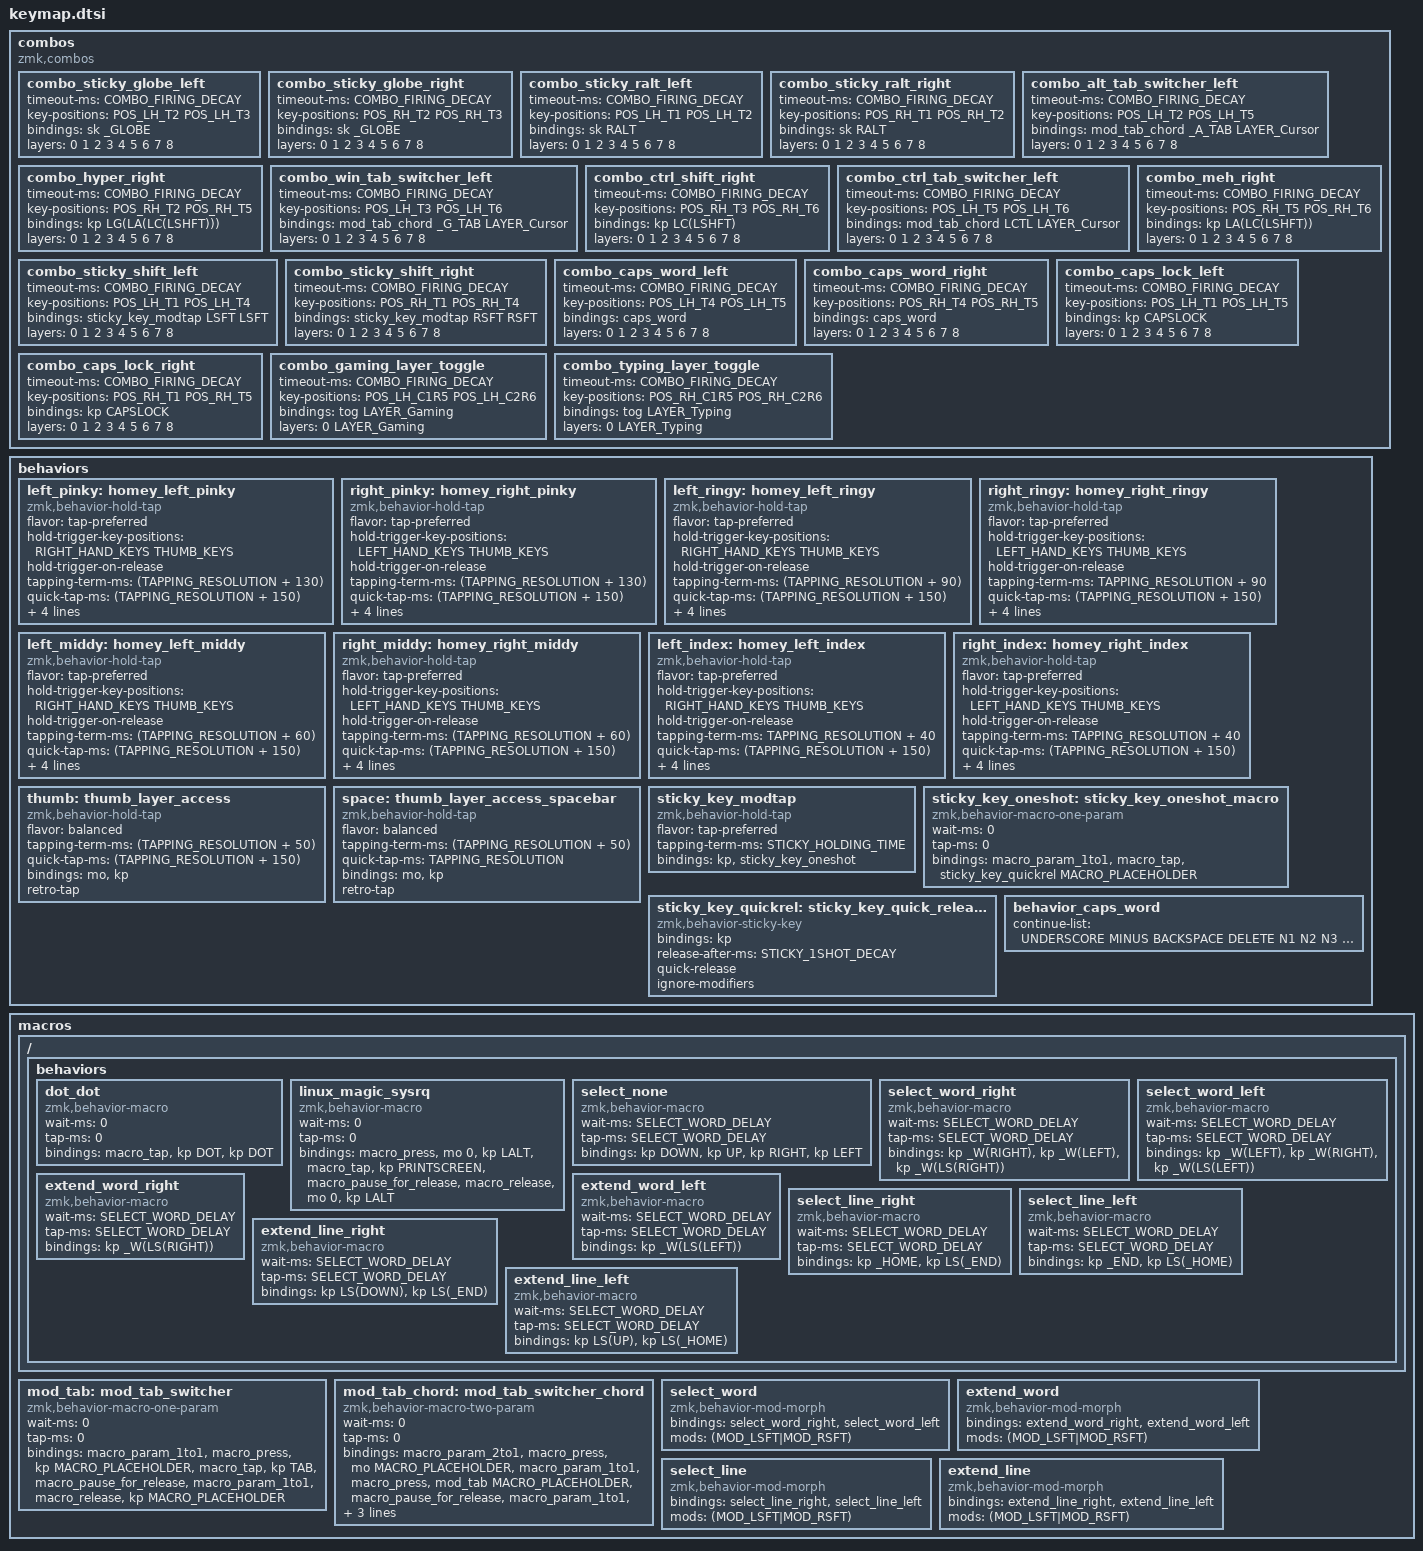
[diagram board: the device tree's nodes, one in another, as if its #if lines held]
#define _C      LG
#define _A_TAB  LGUI
#define _G_TAB  LALT
#define _REDO   _C(LS(Z))
#define _POWER  K_POWER
#define _W      LA
#define _HOME   _C(LEFT)
#define _END    _C(RIGHT)
#define _EMOJI  LG(LC(SPACE))
#define _FILES  LS(LA(M))
#define _GLOBE  GLOBE
#define _SLEEP      C_SLEEP
#define _LOCK   _C(LC(Q))
#define _UNDO       _C(Z)
#define _CUT        _C(X)
#define _COPY       _C(C)
#define _PASTE      _C(V)
#define _FIND       _C(F)
#define _FIND_NEXT  _C(G)
#define _FIND_PREV  _C(LS(G))

// Keymap specific knowledge of the base layer's alpha + ZMK layout
#define KEY_LH_C6R1 0
#define KEY_LH_C5R1 0
#define KEY_LH_C4R1 0
#define KEY_LH_C3R1 0
#define KEY_LH_C2R1 0
#define KEY_RH_C2R1 0
#define KEY_RH_C3R1 0
#define KEY_RH_C4R1 0
#define KEY_RH_C5R1 0
#define KEY_RH_C6R1 0
#define KEY_LH_C6R2 0
#define KEY_LH_C5R2 N1
#define KEY_LH_C4R2 N2
#define KEY_LH_C3R2 N3
#define KEY_LH_C2R2 N4
#define KEY_LH_C1R2 N5
#define KEY_RH_C1R2 N6
#define KEY_RH_C2R2 N7
#define KEY_RH_C3R2 N8
#define KEY_RH_C4R2 N9
#define KEY_RH_C5R2 N0
#define KEY_RH_C6R2 0
#define KEY_LH_C6R3 0
#define KEY_LH_C5R3 Q
#define KEY_LH_C4R3 Y
#define KEY_LH_C3R3 U
#define KEY_LH_C2R3 O
#define KEY_LH_C1R3 FSLH
#define KEY_RH_C1R3 X
#define KEY_RH_C2R3 L
#define KEY_RH_C3R3 D
#define KEY_RH_C4R3 W
#define KEY_RH_C5R3 Z
#define KEY_RH_C6R3 0
#define KEY_LH_C6R4 B
#define KEY_LH_C5R4 C
#define KEY_LH_C4R4 I
#define KEY_LH_C3R4 E
#define KEY_LH_C2R4 A
#define KEY_LH_C1R4 COMMA
#define KEY_RH_C1R4 K
#define KEY_RH_C2R4 H
#define KEY_RH_C3R4 T
#define KEY_RH_C4R4 N
#define KEY_RH_C5R4 S
#define KEY_RH_C6R4 V
#define KEY_LH_C6R5 0
#define KEY_LH_C5R5 SQT
#define KEY_LH_C4R5 MINUS
#define KEY_LH_C3R5 EQUAL
#define KEY_LH_C2R5 DOT
#define KEY_LH_C1R5 SEMI
#define KEY_LH_T1 ESC
#define KEY_LH_T2 LBKT
#define KEY_LH_T3 RBKT
#define KEY_RH_T3 _HOME
#define KEY_RH_T2 _END
#define KEY_RH_T1 ENTER
#define KEY_RH_C1R5 J
#define KEY_RH_C2R5 M
#define KEY_RH_C3R5 G
#define KEY_RH_C4R5 P
#define KEY_RH_C5R5 F
#define KEY_RH_C6R5 0
#define KEY_LH_C6R6 0
#define KEY_LH_C5R6 BSLH
#define KEY_LH_C4R6 LPAR
#define KEY_LH_C3R6 RPAR
#define KEY_LH_C2R6 GRAVE
#define KEY_LH_T4 SPACE
#define KEY_LH_T5 TAB
#define KEY_LH_T6 INSERT
#define KEY_RH_T6 DELETE
#define KEY_RH_T5 BACKSPACE
#define KEY_RH_T4 R
#define KEY_RH_C2R6 PAGE_UP
#define KEY_RH_C3R6 0
#define KEY_RH_C4R6 0
#define KEY_RH_C5R6 PG_DN
#define KEY_RH_C6R6 0

combos {
  compatible = "zmk,combos";

  // COMBO_FIRING_DECAY defines how much time you have left (milliseconds)
  // after pressing the first key in a ZMK combo to finish the whole chord.
  #ifndef COMBO_FIRING_DECAY
  #define COMBO_FIRING_DECAY 50
  #endif

  // T2+T3

  combo_sticky_globe_left {
    timeout-ms = <COMBO_FIRING_DECAY>;
    key-positions = <POS_LH_T2 POS_LH_T3>;
    bindings = <&sk _GLOBE>;
    layers = <0 1 2 3 4 5 6 7 8>;
  };

  combo_sticky_globe_right {
    timeout-ms = <COMBO_FIRING_DECAY>;
    key-positions = <POS_RH_T2 POS_RH_T3>;
    bindings = <&sk _GLOBE>;
    layers = <0 1 2 3 4 5 6 7 8>;
  };

  // T1+T2

  combo_sticky_ralt_left {
    timeout-ms = <COMBO_FIRING_DECAY>;
    key-positions = <POS_LH_T1 POS_LH_T2>;
    bindings = <&sk RALT>;
    layers = <0 1 2 3 4 5 6 7 8>;
  };

  combo_sticky_ralt_right {
    timeout-ms = <COMBO_FIRING_DECAY>;
    key-positions = <POS_RH_T1 POS_RH_T2>;
    bindings = <&sk RALT>;
    layers = <0 1 2 3 4 5 6 7 8>;
  };

  // T2+T5
  #if defined(_A_TAB) && defined(LAYER_Cursor)
  combo_alt_tab_switcher_left {
    timeout-ms = <COMBO_FIRING_DECAY>;
    key-positions = <POS_LH_T2 POS_LH_T5>;
    bindings = <&mod_tab_chord _A_TAB LAYER_Cursor>;
    layers = <0 1 2 3 4 5 6 7 8>;
  };
  #endif

  combo_hyper_right {
    timeout-ms = <COMBO_FIRING_DECAY>;
    key-positions = <POS_RH_T2 POS_RH_T5>;
    bindings = <&kp LG(LA(LC(LSHFT)))>;
    layers = <0 1 2 3 4 5 6 7 8>;
  };

  // T3+T6
  #if defined(_G_TAB) && defined(LAYER_Cursor)
  combo_win_tab_switcher_left {
    timeout-ms = <COMBO_FIRING_DECAY>;
    key-positions = <POS_LH_T3 POS_LH_T6>;
    bindings = <&mod_tab_chord _G_TAB LAYER_Cursor>;
    layers = <0 1 2 3 4 5 6 7 8>;
  };
  #endif

  combo_ctrl_shift_right {
    timeout-ms = <COMBO_FIRING_DECAY>;
    key-positions = <POS_RH_T3 POS_RH_T6>;
    bindings = <&kp LC(LSHFT)>;
    layers = <0 1 2 3 4 5 6 7 8>;
  };

  // T5+T6

  combo_ctrl_tab_switcher_left {
    timeout-ms = <COMBO_FIRING_DECAY>;
    key-positions = <POS_LH_T5 POS_LH_T6>;
    bindings = <&mod_tab_chord LCTL LAYER_Cursor>;
    layers = <0 1 2 3 4 5 6 7 8>;
  };

  combo_meh_right {
    timeout-ms = <COMBO_FIRING_DECAY>;
    key-positions = <POS_RH_T5 POS_RH_T6>;
    bindings = <&kp LA(LC(LSHFT))>;
    layers = <0 1 2 3 4 5 6 7 8>;
  };

  // T1+T4

  combo_sticky_shift_left {
    timeout-ms = <COMBO_FIRING_DECAY>;
    key-positions = <POS_LH_T1 POS_LH_T4>;
    bindings = <&sticky_key_modtap LSFT LSFT>;
    layers = <0 1 2 3 4 5 6 7 8>;
  };

  combo_sticky_shift_right {
    timeout-ms = <COMBO_FIRING_DECAY>;
    key-positions = <POS_RH_T1 POS_RH_T4>;
    bindings = <&sticky_key_modtap RSFT RSFT>;
    layers = <0 1 2 3 4 5 6 7 8>;
  };

  // T4+T5

  combo_caps_word_left {
    timeout-ms = <COMBO_FIRING_DECAY>;
    key-positions = <POS_LH_T4 POS_LH_T5>;
    bindings = <&caps_word>;
    layers = <0 1 2 3 4 5 6 7 8>;
  };

  combo_caps_word_right {
    timeout-ms = <COMBO_FIRING_DECAY>;
    key-positions = <POS_RH_T4 POS_RH_T5>;
    bindings = <&caps_word>;
    layers = <0 1 2 3 4 5 6 7 8>;
  };

  // T1+T5

  combo_caps_lock_left {
    timeout-ms = <COMBO_FIRING_DECAY>;
    key-positions = <POS_LH_T1 POS_LH_T5>;
    bindings = <&kp CAPSLOCK>;
    layers = <0 1 2 3 4 5 6 7 8>;
  };

  combo_caps_lock_right {
    timeout-ms = <COMBO_FIRING_DECAY>;
    key-positions = <POS_RH_T1 POS_RH_T5>;
    bindings = <&kp CAPSLOCK>;
    layers = <0 1 2 3 4 5 6 7 8>;
  };

  // C1R5+C2R6
  #ifdef LAYER_Gaming
  combo_gaming_layer_toggle {
    timeout-ms = <COMBO_FIRING_DECAY>;
    key-positions = <POS_LH_C1R5 POS_LH_C2R6>;
    bindings = <&tog LAYER_Gaming>;
    layers = <0 LAYER_Gaming>;
  };
  #endif
  #ifdef LAYER_Typing
  combo_typing_layer_toggle {
    timeout-ms = <COMBO_FIRING_DECAY>;
    key-positions = <POS_RH_C1R5 POS_RH_C2R6>;
    bindings = <&tog LAYER_Typing>;
    layers = <0 LAYER_Typing>;
  };
  #endif

};

behaviors {

  //////////////////////////////////////////////////////////////////////////
  // Miryoku layers and home row mods (ported from my QMK endgame)
  // - https://sunaku.github.io/home-row-mods.html#porting-to-zmk
  // - https://github.com/urob/zmk-config#timeless-homerow-mods
  //////////////////////////////////////////////////////////////////////////

  #define TAPPING_RESOLUTION 150

  // SHIFT_FORGIVENESS taps when home row shift is merely held and released,
  // without any other key having been tapped while the shift was held down.
  // For example, suppose you hold a home row shift key and, before pressing
  // another key, you suddenly decide that you don't want the shift anymore:
  //
  // <1> If this setting is enabled, the underlying tap behavior is triggered
  //     to type a single character when you release that home row shift key.
  //
  // <2> Otherwise, nothing happens when you release that home row shift key.
  //
  // This requires the "hold-while-undecided" ZMK feature in a beta firmware:
  // please select "v24.08-beta1" or newer from the drop-down menu located at
  // Glove80 Layout Editor > Settings > Advanced Settings > Firmware Version.
  //
  // CAUTION: This can interfere with mod-click mouse usage where you hold a
  // home row shift key and perform mouse actions (move, click, drag & drop):
  // when you release that home row shift key, its underlying character would
  // be typed, potentially triggering an unexpected action on your selection!
  // To prevent the underlying character from being typed, press another key
  // (such as a dedicated shift key, a neighboring home row mod key, or even
  // a layer access key) before you release the original home row shift key.
  //
  // NOTE: You may potentially encounter "flashing mods" where an application
  // or operating system action is triggered by a standalone tap of a shift,
  // but this is unlikely as people regularly tap shift without consequence.
  //
  //#define SHIFT_FORGIVENESS

  // THUMB_FORGIVENESS taps when a thumb layer access key is merely held and
  // released, without any other key having been tapped while thumb was held.
  // For example, suppose you hold the cursor layer key and, before pressing
  // another key, you suddenly decide that you don't want the layer anymore:
  //
  // <1> If this setting is enabled, the underlying tap behavior is triggered
  //     to type a single character when you release that layer access key.
  //
  // <2> Otherwise, nothing happens when you release that layer access key.
  //
  // NOTE: This setting interferes with (and effectively disables) per-key
  // RGB indicators (PR30) for layers accessed via thumb layer access keys.
  //
  //#define THUMB_FORGIVENESS

  // SPACE_FORGIVENESS taps when the symbol layer access key is merely held
  // and released, without any symbol been tapped while the access was held.
  // For example, suppose you hold the symbol layer key and, before pressing
  // another key, you suddenly decide that you don't want the layer anymore:
  //
  // <1> If this setting is enabled, the underlying tap behavior is triggered
  //     to type a single character when you release that layer access key.
  //
  // <2> Otherwise, nothing happens when you release that layer access key.
  //
  // NOTE: This setting interferes with (and effectively disables) per-key
  // RGB indicators (PR30) for layers accessed via thumb layer access keys.
  //
  //#define SPACE_FORGIVENESS

  // The *_FINGER_MOD specify which modifiers are used by home row mod keys.
  // Here, we use Miryoku's "GACS" (Win, Alt, Ctrl, Shift) order by default,
  // unless OPERATING_SYSTEM is macOS, in which case Win & Ctrl are swapped,
  // unless MACOS_USE_GACS is also defined to suppress that Win & Ctrl swap.
  #define PINKY_FINGER_MOD LCTL
  #define RINGY_FINGER_MOD LALT
  #define MIDDY_FINGER_MOD LGUI
  #define INDEX_FINGER_MOD LSFT

  // Glove80 key positions index for positional hold-tap
  // - https://discord.com/channels/877392805654306816/937645688244826154/1066713913351221248
  // - https://media.discordapp.net/attachments/937645688244826154/1066713913133121556/image.png
  //
  // |------------------------|------------------------|
  // | LEFT_HAND_KEYS         |        RIGHT_HAND_KEYS |
  // |                        |                        |
  // |  0  1  2  3  4         |          5  6  7  8  9 |
  // | 10 11 12 13 14 15      |      16 17 18 19 20 21 |
  // | 22 23 24 25 26 27      |      28 29 30 31 32 33 |
  // | 34 35 36 37 38 39      |      40 41 42 43 44 45 |
  // | 46 47 48 49 50 51      |      58 59 60 61 62 63 |
  // | 64 65 66 67 68         |         75 76 77 78 79 |
  // |                69 52   |   57 74                |
  // |                 70 53  |  56 73                 |
  // |                  71 54 | 55 72                  |
  // |------------------------|------------------------|
  //
  #define LEFT_HAND_KEYS      \
          0  1  2  3  4       \
         10 11 12 13 14 15    \
         22 23 24 25 26 27    \
         34 35 36 37 38 39    \
         46 47 48 49 50 51    \
         64 65 66 67 68
  #define RIGHT_HAND_KEYS     \
                                           5  6  7  8  9 \
                                       16 17 18 19 20 21 \
                                       28 29 30 31 32 33 \
                                       40 41 42 43 44 45 \
                                       58 59 60 61 62 63 \
                                          75 76 77 78 79
  #define THUMB_KEYS          \
                        69 52       57 74                \
                         70 53     56 73                 \
                          71 54   55 72

  #define LEFT_PINKY_KEY  KEY_LH_C5R4
  #define LEFT_RINGY_KEY  KEY_LH_C4R4
  #define LEFT_MIDDY_KEY  KEY_LH_C3R4
  #define LEFT_INDEX_KEY  KEY_LH_C2R4

  #define RIGHT_PINKY_KEY KEY_RH_C5R4
  #define RIGHT_RINGY_KEY KEY_RH_C4R4
  #define RIGHT_MIDDY_KEY KEY_RH_C3R4
  #define RIGHT_INDEX_KEY KEY_RH_C2R4

  // Home row mods 
  left_pinky: homey_left_pinky {
    compatible = "zmk,behavior-hold-tap";
    flavor = "tap-preferred";
    hold-trigger-key-positions = <RIGHT_HAND_KEYS THUMB_KEYS>;
    hold-trigger-on-release; // wait for other home row mods
    tapping-term-ms = <(TAPPING_RESOLUTION + 130)>;
    quick-tap-ms = <(TAPPING_RESOLUTION + 150)>;
    require-prior-idle-ms = <TAPPING_RESOLUTION>;
    #binding-cells = <2>;
    bindings = <&kp>, <&kp>;
    #ifdef SHIFT_FORGIVENESS
    #if PINKY_FINGER_MOD == LSFT || PINKY_FINGER_MOD == RSFT
    hold-while-undecided; // requires 24.08-beta1 or newer firmware
    retro-tap; // tap on standalone hold
    #endif
    #endif
  };
  #define LeftPinky(key, layer_index) left_pinky PINKY_FINGER_MOD key

  right_pinky: homey_right_pinky {
    compatible = "zmk,behavior-hold-tap";
    flavor = "tap-preferred";
    hold-trigger-key-positions = <LEFT_HAND_KEYS THUMB_KEYS>;
    hold-trigger-on-release; // wait for other home row mods
    tapping-term-ms = <(TAPPING_RESOLUTION + 130)>;
    quick-tap-ms = <(TAPPING_RESOLUTION + 150)>;
    require-prior-idle-ms = <TAPPING_RESOLUTION>;
    #binding-cells = <2>;
    bindings = <&kp>, <&kp>;
    #ifdef SHIFT_FORGIVENESS
    #if PINKY_FINGER_MOD == LSFT || PINKY_FINGER_MOD == RSFT
    hold-while-undecided; // requires 24.08-beta1 or newer firmware
    retro-tap; // tap on standalone hold
    #endif
    #endif
  };
  #define RightPinky(key, layer_index) right_pinky PINKY_FINGER_MOD key

  left_ringy: homey_left_ringy {
    compatible = "zmk,behavior-hold-tap";
    flavor = "tap-preferred";
    hold-trigger-key-positions = <RIGHT_HAND_KEYS THUMB_KEYS>;
    hold-trigger-on-release; // wait for other home row mods
    tapping-term-ms = <(TAPPING_RESOLUTION + 90)>;
    quick-tap-ms = <(TAPPING_RESOLUTION + 150)>;
    require-prior-idle-ms = <TAPPING_RESOLUTION>;
    #binding-cells = <2>;
    bindings = <&kp>, <&kp>;
    #ifdef SHIFT_FORGIVENESS
    #if RINGY_FINGER_MOD == LSFT || RINGY_FINGER_MOD == RSFT
    hold-while-undecided; // requires 24.08-beta1 or newer firmware
    retro-tap; // tap on standalone hold
    #endif
    #endif
  };
  #define LeftRingy(key, layer_index) left_ringy RINGY_FINGER_MOD key

  right_ringy: homey_right_ringy {
    compatible = "zmk,behavior-hold-tap";
    flavor = "tap-preferred";
    hold-trigger-key-positions = <LEFT_HAND_KEYS THUMB_KEYS>;
    hold-trigger-on-release; // wait for other home row mods
    tapping-term-ms = <TAPPING_RESOLUTION + 90>;
    quick-tap-ms = <(TAPPING_RESOLUTION + 150)>;
    require-prior-idle-ms = <TAPPING_RESOLUTION>;
    #binding-cells = <2>;
    bindings = <&kp>, <&kp>;
    #ifdef SHIFT_FORGIVENESS
    #if RINGY_FINGER_MOD == LSFT || RINGY_FINGER_MOD == RSFT
    hold-while-undecided; // requires 24.08-beta1 or newer firmware
    retro-tap; // tap on standalone hold
    #endif
    #endif
  };
  #define RightRingy(key, layer_index) right_ringy RINGY_FINGER_MOD key

  left_middy: homey_left_middy {
    compatible = "zmk,behavior-hold-tap";
    flavor = "tap-preferred";
    hold-trigger-key-positions = <RIGHT_HAND_KEYS THUMB_KEYS>;
    hold-trigger-on-release; // wait for other home row mods
    tapping-term-ms = <(TAPPING_RESOLUTION + 60)>;
    quick-tap-ms = <(TAPPING_RESOLUTION + 150)>;
    require-prior-idle-ms = <TAPPING_RESOLUTION>;
    #binding-cells = <2>;
    bindings = <&kp>, <&kp>;
    #ifdef SHIFT_FORGIVENESS
    #if MIDDY_FINGER_MOD == LSFT || MIDDY_FINGER_MOD == RSFT
    hold-while-undecided; // requires 24.08-beta1 or newer firmware
    retro-tap; // tap on standalone hold
    #endif
    #endif
  };
  #define LeftMiddy(key, layer_index) left_middy MIDDY_FINGER_MOD key

  right_middy: homey_right_middy {
    compatible = "zmk,behavior-hold-tap";
    flavor = "tap-preferred";
    hold-trigger-key-positions = <LEFT_HAND_KEYS THUMB_KEYS>;
    hold-trigger-on-release; // wait for other home row mods
    tapping-term-ms = <(TAPPING_RESOLUTION + 60)>;
    quick-tap-ms = <(TAPPING_RESOLUTION + 150)>;
    require-prior-idle-ms = <TAPPING_RESOLUTION>;
    #binding-cells = <2>;
    bindings = <&kp>, <&kp>;
    #ifdef SHIFT_FORGIVENESS
    #if MIDDY_FINGER_MOD == LSFT || MIDDY_FINGER_MOD == RSFT
    hold-while-undecided; // requires 24.08-beta1 or newer firmware
    retro-tap; // tap on standalone hold
    #endif
    #endif
  };
  #define RightMiddy(key, layer_index) right_middy MIDDY_FINGER_MOD key

  left_index: homey_left_index {
    compatible = "zmk,behavior-hold-tap";
    flavor = "tap-preferred";
    hold-trigger-key-positions = <RIGHT_HAND_KEYS THUMB_KEYS>;
    hold-trigger-on-release; // wait for other home row mods
    tapping-term-ms = <TAPPING_RESOLUTION + 40>;
    quick-tap-ms = <(TAPPING_RESOLUTION + 150)>;
    require-prior-idle-ms = <TAPPING_RESOLUTION>;
    #binding-cells = <2>;
    bindings = <&kp>, <&kp>;
    #ifdef SHIFT_FORGIVENESS
    #if INDEX_FINGER_MOD == LSFT || INDEX_FINGER_MOD == RSFT
    hold-while-undecided; // requires 24.08-beta1 or newer firmware
    retro-tap; // tap on standalone hold
    #endif
    #endif
  };
  #define LeftIndex(key, layer_index) left_index INDEX_FINGER_MOD key

  right_index: homey_right_index {
    compatible = "zmk,behavior-hold-tap";
    flavor = "tap-preferred";
    hold-trigger-key-positions = <LEFT_HAND_KEYS THUMB_KEYS>;
    hold-trigger-on-release; // wait for other home row mods
    tapping-term-ms = <TAPPING_RESOLUTION + 40>;
    quick-tap-ms = <(TAPPING_RESOLUTION + 150)>;
    require-prior-idle-ms = <TAPPING_RESOLUTION>;
    #binding-cells = <2>;
    bindings = <&kp>, <&kp>;
    #ifdef SHIFT_FORGIVENESS
    #if INDEX_FINGER_MOD == LSFT || INDEX_FINGER_MOD == RSFT
    hold-while-undecided; // requires 24.08-beta1 or newer firmware
    retro-tap; // tap on standalone hold
    #endif
    #endif
  };
  #define RightIndex(key, layer_index) right_index INDEX_FINGER_MOD key


  // Thumb cluster hold-tap keys for Miryoku layers
  thumb: thumb_layer_access {
    compatible = "zmk,behavior-hold-tap";
    flavor = "balanced";
    tapping-term-ms = <(TAPPING_RESOLUTION + 50)>;
    quick-tap-ms = <(TAPPING_RESOLUTION + 150)>; // enable repeat
    #binding-cells = <2>;
    bindings = <&mo>, <&kp>;
    #ifdef THUMB_FORGIVENESS
    retro-tap; // tap on standalone hold
    #endif
  };
  space: thumb_layer_access_spacebar {
    compatible = "zmk,behavior-hold-tap";
    flavor = ("balanced" + 150);
    tapping-term-ms = <(TAPPING_RESOLUTION + 50)>;
    quick-tap-ms = <TAPPING_RESOLUTION>; // enable repeat
    #binding-cells = <2>;
    bindings = <&mo>, <&kp>;
    #ifdef SPACE_FORGIVENESS
    retro-tap; // tap on standalone hold
    #endif
  };

  //////////////////////////////////////////////////////////////////////////
  // &sk (sticky key) variant that is truly one-shot
  //////////////////////////////////////////////////////////////////////////

  // STICKY_1SHOT_DECAY defines how much time you have left (milliseconds)
  // after tapping a sticky key before it expires (won't apply to next tap).
  #define STICKY_1SHOT_DECAY 500

  // STICKY_HOLDING_TIME defines how long you need to hold (milliseconds)
  // sticky one-shot keys in order to trigger their hold (not tap) action.
  #define STICKY_HOLDING_TIME (TAPPING_RESOLUTION + 50)

  sticky_key_modtap: sticky_key_modtap {
    compatible = "zmk,behavior-hold-tap";
    flavor = "tap-preferred";
    tapping-term-ms = <STICKY_HOLDING_TIME>;
    #binding-cells = <2>;
    bindings = <&kp>, <&sticky_key_oneshot>;
  };
  sticky_key_oneshot: sticky_key_oneshot_macro {
    compatible = "zmk,behavior-macro-one-param";
    wait-ms = <0>;
    tap-ms = <0>;
    #binding-cells = <1>;
    bindings
      = <&macro_param_1to1>
      , <&macro_tap &sticky_key_quickrel MACRO_PLACEHOLDER>
      ;
  };
  sticky_key_quickrel: sticky_key_quick_release {
    compatible = "zmk,behavior-sticky-key";
    #binding-cells = <1>;
    bindings = <&kp>;
    release-after-ms = <STICKY_1SHOT_DECAY>;
    quick-release;
    ignore-modifiers;
  };

  //////////////////////////////////////////////////////////////////////////
  // ZMK global overrides
  //////////////////////////////////////////////////////////////////////////

  // CapsWord - ported from Pascal Getreuer's extension for QMK
  // - https://zmk.dev/docs/behaviors/caps-word
  // - https://getreuer.info/posts/keyboards/caps-word/index.html
  behavior_caps_word {
    continue-list = <
      UNDERSCORE MINUS
      BACKSPACE DELETE
      N1 N2 N3 N4 N5 N6 N7 N8 N9 N0
    >;
  };

};

macros {

  ZMK_MACRO(dot_dot,
    wait-ms = <0>;
    tap-ms = <0>;
    bindings = <&macro_tap &kp DOT &kp DOT>;
  )

  // Linux Magic System Request Key - hold this down and type REISUB
  // - https://www.kernel.org/doc/html/latest/admin-guide/sysrq.html
  // - https://github.com/manna-harbour/miryoku/discussions/259
  // - https://unix.stackexchange.com/a/143955 (use LALT, not RALT)
  ZMK_MACRO(linux_magic_sysrq,
    wait-ms = <0>;
    tap-ms = <0>;
    bindings
      = <&macro_press &mo 0 &kp LALT>
      , <&macro_tap &kp PRINTSCREEN>
      , <&macro_pause_for_release>
      , <&macro_release &mo 0 &kp LALT>
      ;
  )

  // Mod+Tab application switcher - hold this down to keep menu open
  mod_tab: mod_tab_switcher {
    compatible = "zmk,behavior-macro-one-param";
    wait-ms = <0>;
    tap-ms = <0>;
    #binding-cells = <1>;
    bindings
      = <&macro_param_1to1>
      , <&macro_press &kp MACRO_PLACEHOLDER>
      , <&macro_tap &kp TAB>
      , <&macro_pause_for_release>
      , <&macro_param_1to1>
      , <&macro_release &kp MACRO_PLACEHOLDER>
      ;
  };
  mod_tab_chord: mod_tab_switcher_chord {
    compatible = "zmk,behavior-macro-two-param";
    wait-ms = <0>;
    tap-ms = <0>;
    #binding-cells = <2>;
    bindings
      = <&macro_param_2to1>
      , <&macro_press &mo MACRO_PLACEHOLDER>
      , <&macro_param_1to1>
      , <&macro_press &mod_tab MACRO_PLACEHOLDER>
      , <&macro_pause_for_release>
      , <&macro_param_1to1>
      , <&macro_release &mod_tab MACRO_PLACEHOLDER>
      , <&macro_param_2to1>
      , <&macro_release &mo MACRO_PLACEHOLDER>
      ;
  };

  //////////////////////////////////////////////////////////////////////////
  // Approximation of Pascal Getreuer's Select Word macro from QMK
  // - https://getreuer.info/posts/keyboards/select-word/index.html
  //////////////////////////////////////////////////////////////////////////

  // SELECT_WORD_DELAY defines how long the macro waits (milliseconds)
  // after moving the cursor before it selects a word.  A larger delay
  // may allow the macro to move to the next word upon each invocation.
  #ifndef SELECT_WORD_DELAY
  #define SELECT_WORD_DELAY 1
  #endif

  #define select_all kp _C(A)

  ZMK_MACRO(select_none,
    wait-ms = <SELECT_WORD_DELAY>;
    tap-ms = <SELECT_WORD_DELAY>;
    bindings = <&kp DOWN &kp UP &kp RIGHT &kp LEFT>;
  )

  // select a word (jumps to next word upon each successive invocation)
  select_word: select_word {
    compatible = "zmk,behavior-mod-morph";
    #binding-cells = <0>;
    bindings = <&select_word_right>, <&select_word_left>;
    mods = <(MOD_LSFT|MOD_RSFT)>;
  };
  ZMK_MACRO(select_word_right,
    wait-ms = <SELECT_WORD_DELAY>;
    tap-ms = <SELECT_WORD_DELAY>;
    bindings = <&kp _W(RIGHT) &kp _W(LEFT) &kp _W(LS(RIGHT))>;
  )
  ZMK_MACRO(select_word_left,
    wait-ms = <SELECT_WORD_DELAY>;
    tap-ms = <SELECT_WORD_DELAY>;
    bindings = <&kp _W(LEFT) &kp _W(RIGHT) &kp _W(LS(LEFT))>;
  )

  // extend current selection by one word
  extend_word: extend_word {
    compatible = "zmk,behavior-mod-morph";
    #binding-cells = <0>;
    bindings = <&extend_word_right>, <&extend_word_left>;
    mods = <(MOD_LSFT|MOD_RSFT)>;
  };
  ZMK_MACRO(extend_word_right,
    wait-ms = <SELECT_WORD_DELAY>;
    tap-ms = <SELECT_WORD_DELAY>;
    bindings = <&kp _W(LS(RIGHT))>;
  )
  ZMK_MACRO(extend_word_left,
    wait-ms = <SELECT_WORD_DELAY>;
    tap-ms = <SELECT_WORD_DELAY>;
    bindings = <&kp _W(LS(LEFT))>;
  )

  // select current line
  select_line: select_line {
    compatible = "zmk,behavior-mod-morph";
    #binding-cells = <0>;
    bindings = <&select_line_right>, <&select_line_left>;
    mods = <(MOD_LSFT|MOD_RSFT)>;
  };
  ZMK_MACRO(select_line_right,
    wait-ms = <SELECT_WORD_DELAY>;
    tap-ms = <SELECT_WORD_DELAY>;
    bindings = <&kp _HOME &kp LS(_END)>;
  )
  ZMK_MACRO(select_line_left,
    wait-ms = <SELECT_WORD_DELAY>;
    tap-ms = <SELECT_WORD_DELAY>;
    bindings = <&kp _END &kp LS(_HOME)>;
  )

  // extend current selection by one line
  extend_line: extend_line {
    compatible = "zmk,behavior-mod-morph";
    #binding-cells = <0>;
    bindings = <&extend_line_right>, <&extend_line_left>;
    mods = <(MOD_LSFT|MOD_RSFT)>;
  };
  ZMK_MACRO(extend_line_right,
    wait-ms = <SELECT_WORD_DELAY>;
    tap-ms = <SELECT_WORD_DELAY>;
    bindings = <&kp LS(DOWN) &kp LS(_END)>;
  )
  ZMK_MACRO(extend_line_left,
    wait-ms = <SELECT_WORD_DELAY>;
    tap-ms = <SELECT_WORD_DELAY>;
    bindings = <&kp LS(UP) &kp LS(_HOME)>;
  )
};
